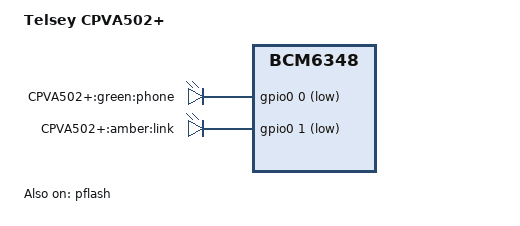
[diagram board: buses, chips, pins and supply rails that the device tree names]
/dts-v1/;

#include "bcm6348.dtsi"

#include <dt-bindings/input/input.h>

/ {
	model = "Telsey CPVA502+";
	compatible = "telsey,cpva502+", "brcm,bcm6348";

	gpio-leds {
		compatible = "gpio-leds";

		power_green {
			label = "CPVA502+:green:phone";
			gpios = <&gpio0 0 1>;
		};

		status {
			label = "CPVA502+:amber:link";
			gpios = <&gpio0 1 1>;
		};
	};
};

&pflash {
	status = "ok";

	linux,part-probe = "bcm63xxpart";

	cfe@0 {
		label = "CFE";
		reg = <0x000000 0x010000>;
		read-only;
	};

	linux@10000 {
		label = "linux";
		reg = <0x010000 0x3e0000>;
	};

	nvram@3f0000 {
		label = "nvram";
		reg = <0x3f0000 0x010000>;
	};
};
